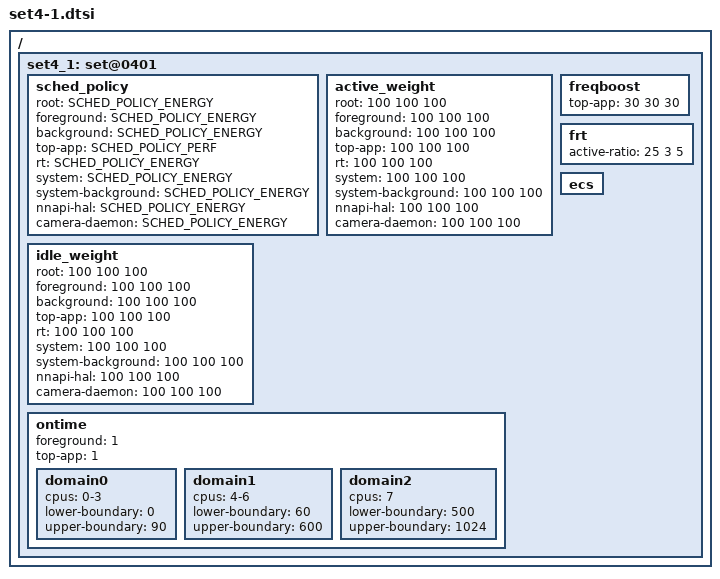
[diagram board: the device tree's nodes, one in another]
/ {
	/* balance mode - touch boost */
	set4_1: set@0401{
		/* schedudling policy */
		sched_policy {
			root			= <SCHED_POLICY_ENERGY>;
			foreground 		= <SCHED_POLICY_ENERGY>;
			background		= <SCHED_POLICY_ENERGY>;
			top-app			= <SCHED_POLICY_PERF>;
			rt			= <SCHED_POLICY_ENERGY>;
			system			= <SCHED_POLICY_ENERGY>;
			system-background	= <SCHED_POLICY_ENERGY>;
			nnapi-hal		= <SCHED_POLICY_ENERGY>;
			camera-daemon		= <SCHED_POLICY_ENERGY>;
		};

		/* weight (%) applied to active cpu's efficiency */
		active_weight {	   		/* LIT MED BIG */
			root            	= <100 100 100>;
			foreground      	= <100 100 100>;
			background      	= <100 100 100>;
			top-app         	= <100 100 100>;
			rt			= <100 100 100>;
			system			= <100 100 100>;
			system-background	= <100 100 100>;
			nnapi-hal		= <100 100 100>;
			camera-daemon		= <100 100 100>;
		};

		/* weight (%) applied to idle cpu's efficiency */
		idle_weight {	   		/* LIT MED BIG */
			root            	= <100 100 100>;
			foreground      	= <100 100 100>;
			background      	= <100 100 100>;
			top-app         	= <100 100 100>;
			rt			= <100 100 100>;
			system			= <100 100 100>;
			system-background	= <100 100 100>;
			nnapi-hal		= <100 100 100>;
			camera-daemon		= <100 100 100>;
		};

		/* Boosting margin applied to frequency selection */
		freqboost {	   		/* LIT MED BIG */
			top-app         	= < 30 30 30>;
		};

		frt {	   			/* LIT MED BIG */
			active-ratio 		= < 25   3   5>;
		};

		/* Ontime Migration */
		ontime {
			foreground 	= <1>;
			top-app		= <1>;

			domain0 {
				cpus = "0-3";
				lower-boundary = <0>;
				upper-boundary = <90>;
			};
			domain1 {
				cpus = "4-6";
				lower-boundary = <60>;
				upper-boundary = <600>;
			};
			domain2 {
				cpus = "7";
				lower-boundary = <500>;
				upper-boundary = <1024>;
			};
		};

		ecs { };
	};
};
